# M4KL register map
File version: 0.1
Registers are 32-bit, read-write, reset 0x0 unless marked. A register's access mark holds for its fields unless they carry their own. Offsets are from the block's base; [hi:lo] are bit positions; {n}, {i} and the like mark numbered series.

## ADA — 12-bit Analog to Digital Converter(ADC)
Base 0x400BA000
Same registers: ADB 0x400BA400, ADC 0x400BA800
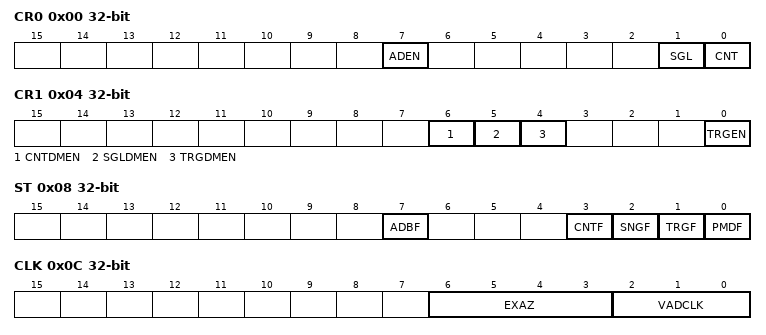
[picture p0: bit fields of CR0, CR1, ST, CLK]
0x00 CR0 — AD Control Register 0
  [7] ADEN, [1] SGL wo, [0] CNT
0x04 CR1 — AD Control Register 1
  [6] CNTDMEN, [5] SGLDMEN, [4] TRGDMEN, [0] TRGEN
0x08 ST ro — AD Status Register
  [7] ADBF, [3] CNTF, [2] SNGF, [1] TRGF, [0] PMDF
0x0C CLK — AD Conversion Clock Setting Register
  [6:3] EXAZ, [2:0] VADCLK
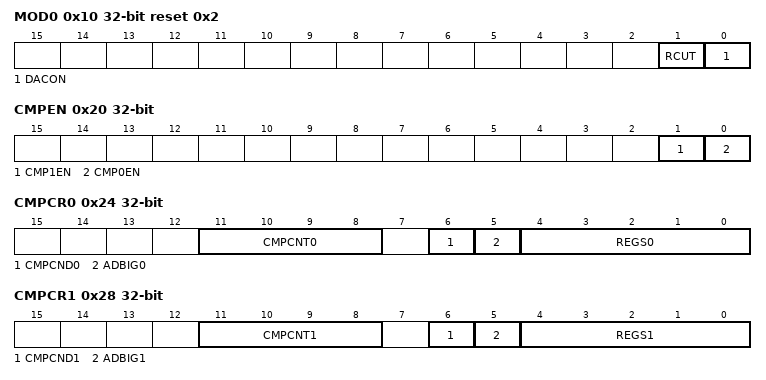
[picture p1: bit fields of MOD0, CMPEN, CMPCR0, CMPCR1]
0x10 MOD0 reset 0x2 — AD Mode Control Register 0
  [1] RCUT, [0] DACON
0x14 MOD1 reset 0x4000 — AD Mode Control Register 1
0x18 MOD2 — AD Mode Control Register 2
0x20 CMPEN — AD Monitor function interrupt permission register
  [1] CMP1EN, [0] CMP0EN
0x24 CMPCR0 — AD Monitor function Setting Register 0
  [11:8] CMPCNT0, [6] CMPCND0, [5] ADBIG0, [4:0] REGS0
0x28 CMPCR1 — AD Monitor function Setting Register 1
  [11:8] CMPCNT1, [6] CMPCND1, [5] ADBIG1, [4:0] REGS1
0x2C CMP0 — AD Conversion Result Comparison Register 0
  [15:4] AD0CMP0
0x30 CMP1 — AD Conversion Result Comparison Register 1
  [15:4] AD0CMP1
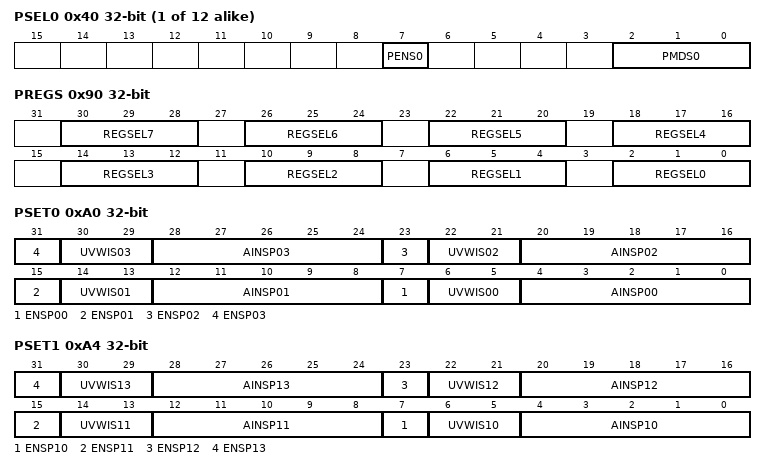
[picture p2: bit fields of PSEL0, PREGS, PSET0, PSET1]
{0x40+4i} PSEL{i} (i=0..11) — AD PMD Trigger Program Number Select Register {i}
  [7] PENS{i}, [2:0] PMDS{i}
{0x70+4i} PINTS{i} (i=0..7) — AD PMD Trigger Interrupt Select Register {i}
  [1:0] INTSEL{i}
0x90 PREGS — AD PMD Trigger Conversion Result Storage Select Register 1
  [4n+2:4n] REGSEL{n} (n=0..7)
0xA0 PSET0 — AD PMD Trigger Program Register 0
  [8n+7] ENSP{n:02} (n=0..3), [8n+6:8n+5] UVWIS{n:02} (n=0..3), [8n+4:8n] AINSP{n:02} (n=0..3)
0xA4 PSET1 — AD PMD Trigger Program Register 1
  [8n-73] ENSP{n} (n=10..13), [8n-74:8n-75] UVWIS{n} (n=10..13), [8n-76:8n-80] AINSP{n} (n=10..13)
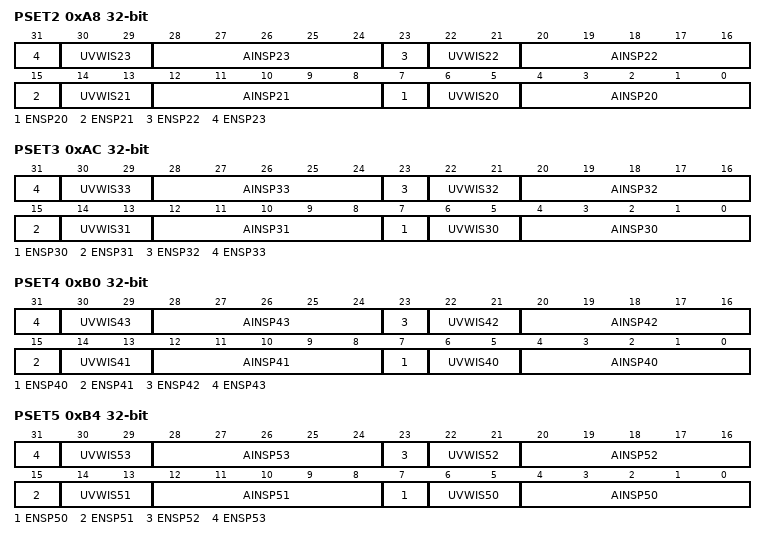
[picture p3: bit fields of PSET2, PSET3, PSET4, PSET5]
0xA8 PSET2 — AD PMD Trigger Program Register 2
  [8n-153] ENSP{n} (n=20..23), [8n-154:8n-155] UVWIS{n} (n=20..23), [8n-156:8n-160] AINSP{n} (n=20..23)
0xAC PSET3 — AD PMD Trigger Program Register 3
  [8n-233] ENSP{n} (n=30..33), [8n-234:8n-235] UVWIS{n} (n=30..33), [8n-236:8n-240] AINSP{n} (n=30..33)
0xB0 PSET4 — AD PMD Trigger Program Register 4
  [8n-313] ENSP{n} (n=40..43), [8n-314:8n-315] UVWIS{n} (n=40..43), [8n-316:8n-320] AINSP{n} (n=40..43)
0xB4 PSET5 — AD PMD Trigger Program Register 5
  [8n-393] ENSP{n} (n=50..53), [8n-394:8n-395] UVWIS{n} (n=50..53), [8n-396:8n-400] AINSP{n} (n=50..53)
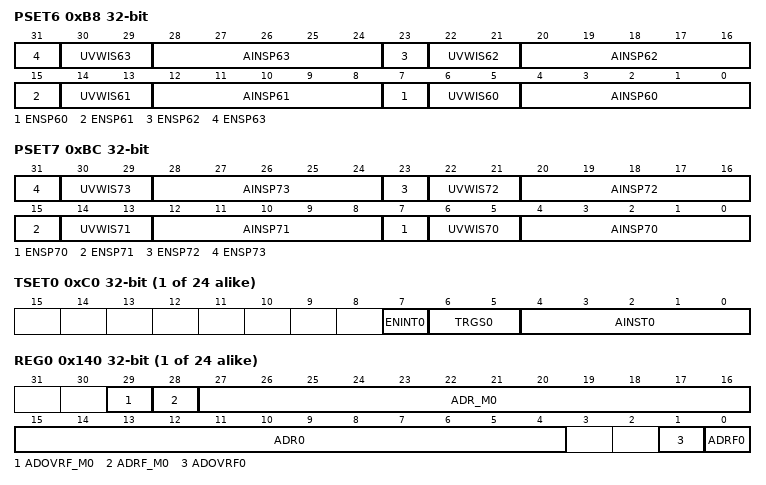
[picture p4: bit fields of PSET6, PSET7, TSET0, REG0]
0xB8 PSET6 — AD PMD Trigger Program Register 6
  [8n-473] ENSP{n} (n=60..63), [8n-474:8n-475] UVWIS{n} (n=60..63), [8n-476:8n-480] AINSP{n} (n=60..63)
0xBC PSET7 — AD PMD Trigger Program Register 7
  [8n-553] ENSP{n} (n=70..73), [8n-554:8n-555] UVWIS{n} (n=70..73), [8n-556:8n-560] AINSP{n} (n=70..73)
{0xC0+4i} TSET{i} (i=0..23) — AD General purpose Trigger Program Register {i}
  [7] ENINT{i}, [6:5] TRGS{i}, [4:0] AINST{i}
{0x140+4i} REG{i} ro (i=0..23) — AD Conversion Result Register {i}
  [29] ADOVRF_M{i}, [28] ADRF_M{i}, [27:16] ADR_M{i}, [15:4] ADR{i}, [1] ADOVRF{i}, [0] ADRF{i}

## AMP — Gain Op-AMP (AMP)
Base 0x400BD000
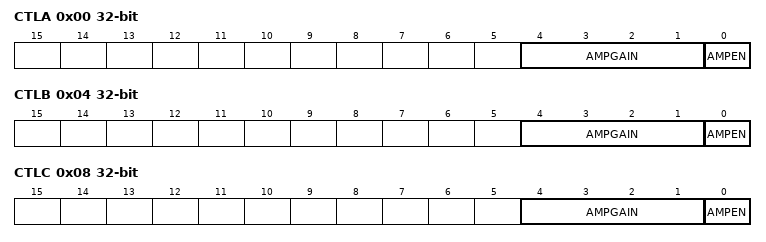
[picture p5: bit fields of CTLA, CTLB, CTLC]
0x00 CTLA — AMP control register A
  [4:1] AMPGAIN, [0] AMPEN
0x04 CTLB — AMP control register B
  [4:1] AMPGAIN, [0] AMPEN
0x08 CTLC — AMP control register C
  [4:1] AMPGAIN, [0] AMPEN

## T32A0 — 32-bit Timer Event Counter (T32A)
Base 0x400C1000
Same registers: T32A1 0x400C1400, T32A2 0x400C1800, T32A3 0x400C1C00, T32A4 0x400C2000, T32A5 0x400C2400
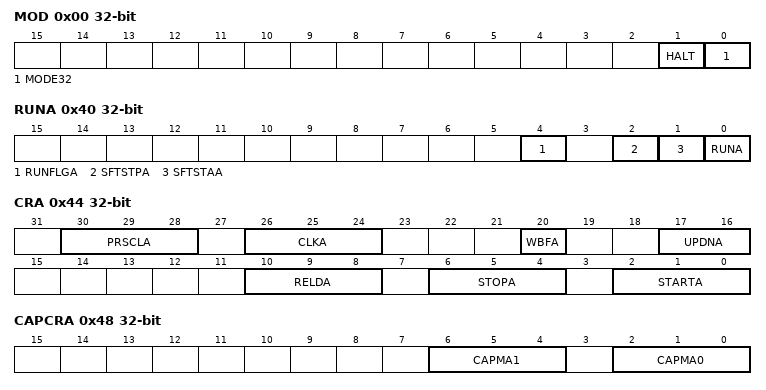
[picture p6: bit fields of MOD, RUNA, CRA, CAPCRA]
0x00 MOD — T32A Mode Register
  [1] HALT, [0] MODE32
0x40 RUNA — T32A Run Register A
  [4] RUNFLGA ro, [2] SFTSTPA wo, [1] SFTSTAA wo, [0] RUNA
0x44 CRA — T32A Control Register A
  [30:28] PRSCLA, [26:24] CLKA, [20] WBFA, [17:16] UPDNA, [10:8] RELDA, [6:4] STOPA, [2:0] STARTA
0x48 CAPCRA — T32A Capture Control Register A
  [6:4] CAPMA1, [2:0] CAPMA0
0x4C OUTCRA0 wo — T32A Output Control Register A0
  [1:0] OCRA
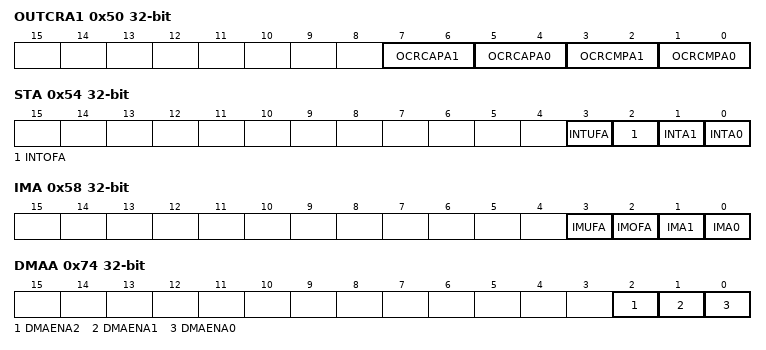
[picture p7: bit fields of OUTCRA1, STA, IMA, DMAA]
0x50 OUTCRA1 — T32A Output Control Register A1
  [7:6] OCRCAPA1, [5:4] OCRCAPA0, [3:2] OCRCMPA1, [1:0] OCRCMPA0
0x54 STA — T32A Status Register A
  [3] INTUFA, [2] INTOFA, [1] INTA1, [0] INTA0
0x58 IMA — T32A Interrupt Mask Register A
  [3] IMUFA, [2] IMOFA, [1] IMA1, [0] IMA0
0x5C TMRA ro — T32A Counter Capture Register A
  [15:0] TMRA
0x60 RELDA — T32A Reload Register A
  [15:0] RELDA
0x64 RGA0 — T32A Timer Register A0
  [15:0] RGA0
0x68 RGA1 — T32A Timer Register A1
  [15:0] RGA1
0x6C CAPA0 ro — T32A Capture Register A0
  [15:0] CAPA0
0x70 CAPA1 ro — T32A Capture Register A1
  [15:0] CAPA1
0x74 DMAA — T32A DMA Request Enable Register A
  [2] DMAENA2, [1] DMAENA1, [0] DMAENA0
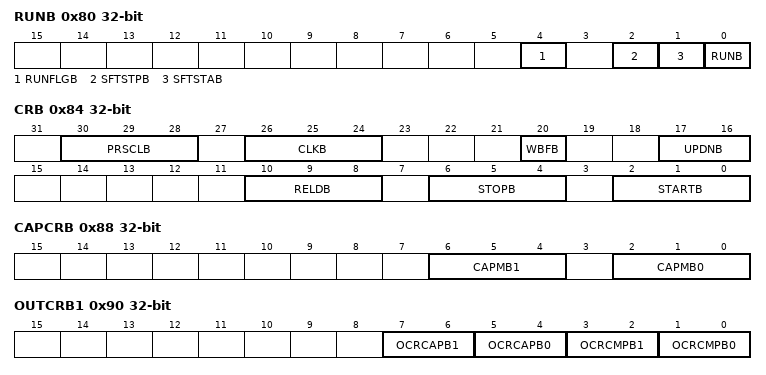
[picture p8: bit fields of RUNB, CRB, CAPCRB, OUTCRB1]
0x80 RUNB — T32A Run Register B
  [4] RUNFLGB ro, [2] SFTSTPB wo, [1] SFTSTAB wo, [0] RUNB
0x84 CRB — T32A Control Register B
  [30:28] PRSCLB, [26:24] CLKB, [20] WBFB, [17:16] UPDNB, [10:8] RELDB, [6:4] STOPB, [2:0] STARTB
0x88 CAPCRB — T32A Capture Control Register B
  [6:4] CAPMB1, [2:0] CAPMB0
0x8C OUTCRB0 wo — T32A Output Control Register B0
  [1:0] OCRB
0x90 OUTCRB1 — T32A Output Control Register B1
  [7:6] OCRCAPB1, [5:4] OCRCAPB0, [3:2] OCRCMPB1, [1:0] OCRCMPB0
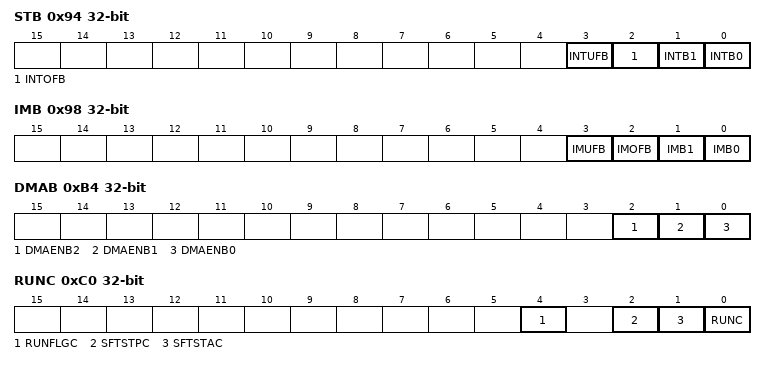
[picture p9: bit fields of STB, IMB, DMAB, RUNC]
0x94 STB — T32A Status Register B
  [3] INTUFB, [2] INTOFB, [1] INTB1, [0] INTB0
0x98 IMB — T32A Interrupt Mask Register B
  [3] IMUFB, [2] IMOFB, [1] IMB1, [0] IMB0
0x9C TMRB ro — T32A Counter Capture Register B
  [15:0] TMRB
0xA0 RELDB — T32A Reload Register B
  [15:0] RELDB
0xA4 RGB0 — T32A Timer Register B0
  [15:0] RGB0
0xA8 RGB1 — T32A Timer Register B1
  [15:0] RGB1
0xAC CAPB0 ro — T32A Capture Register B0
  [15:0] CAPB0
0xB0 CAPB1 ro — T32A Capture Register B1
  [15:0] CAPB1
0xB4 DMAB — T32A DMA Request Enable Register B
  [2] DMAENB2, [1] DMAENB1, [0] DMAENB0
0xC0 RUNC — T32A Run Register C
  [4] RUNFLGC ro, [2] SFTSTPC wo, [1] SFTSTAC wo, [0] RUNC
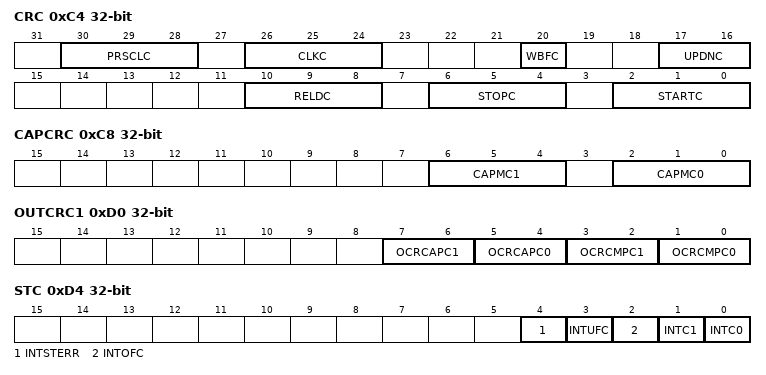
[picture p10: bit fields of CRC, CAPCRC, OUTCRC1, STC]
0xC4 CRC — T32A Control Register C
  [30:28] PRSCLC, [26:24] CLKC, [20] WBFC, [17:16] UPDNC, [10:8] RELDC, [6:4] STOPC, [2:0] STARTC
0xC8 CAPCRC — T32A Capture Control Register C
  [6:4] CAPMC1, [2:0] CAPMC0
0xCC OUTCRC0 wo — T32A Output Control Register C0
  [1:0] OCRC
0xD0 OUTCRC1 — T32A Output Control Register C1
  [7:6] OCRCAPC1, [5:4] OCRCAPC0, [3:2] OCRCMPC1, [1:0] OCRCMPC0
0xD4 STC — T32A Status Register C
  [4] INTSTERR, [3] INTUFC, [2] INTOFC, [1] INTC1, [0] INTC0
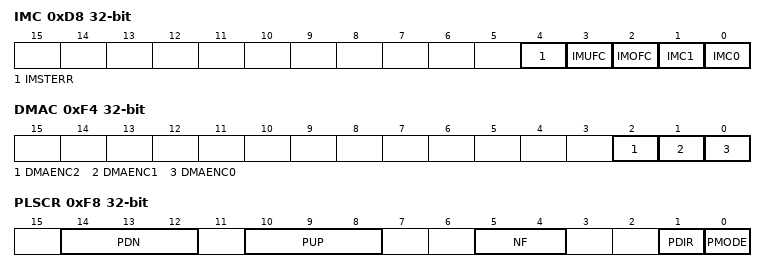
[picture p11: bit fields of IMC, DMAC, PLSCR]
0xD8 IMC — T32A Interrupt Mask Register C
  [4] IMSTERR, [3] IMUFC, [2] IMOFC, [1] IMC1, [0] IMC0
0xDC TMRC ro — T32A Counter Capture Register C
0xE0 RELDC — T32A Reload Register C
0xE4 RGC0 — T32A Timer Register C0
0xE8 RGC1 — T32A Timer Register C1
0xEC CAPC0 ro — T32A Capture Register C0
0xF0 CAPC1 ro — T32A Capture Register C1
0xF4 DMAC — T32A DMA Request Enable Register C
  [2] DMAENC2, [1] DMAENC1, [0] DMAENC0
0xF8 PLSCR — T32A Pulse Count Control Register
  [14:12] PDN, [10:8] PUP, [5:4] NF, [1] PDIR, [0] PMODE
